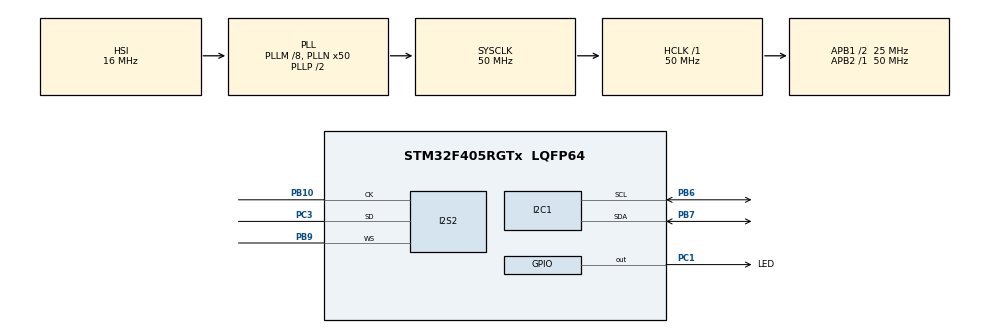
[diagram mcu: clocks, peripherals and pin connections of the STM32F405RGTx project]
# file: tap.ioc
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I2C1.I2C_Mode=I2C_Fast
I2S2.AudioFreq=I2S_AUDIOFREQ_11K
I2S2.ErrorAudioFreq=0.02 %
I2S2.FullDuplexMode=I2S_FULLDUPLEXMODE_DISABLE
I2S2.Instance=SPI$Index
I2S2.RealAudioFreq=11.003 KHz
I2S2.VirtualMode=I2S_MODE_MASTER
Mcu.Family=STM32F4
Mcu.Name=STM32F405RGTx
Mcu.Package=LQFP64
NVIC.PriorityGroup=NVIC_PRIORITYGROUP_4
PB10.Mode=Half_Duplex_Master
PB10.Signal=I2S2_CK
PB6.Mode=I2C
PB6.Signal=I2C1_SCL
PB7.Mode=I2C
PB7.Signal=I2C1_SDA
PB9.Mode=Half_Duplex_Master
PB9.Signal=I2S2_WS
PC1.GPIO_Label=LED
PC1.Signal=GPIO_Output
PC14-OSC32_IN.Mode=LSE-External-Oscillator
PC14-OSC32_IN.Signal=RCC_OSC32_IN
PC15-OSC32_OUT.Mode=LSE-External-Oscillator
PC15-OSC32_OUT.Signal=RCC_OSC32_OUT
PC3.Mode=Half_Duplex_Master
PC3.Signal=I2S2_SD
PH0-OSC_IN.Mode=HSE-External-Oscillator
PH0-OSC_IN.Signal=RCC_OSC_IN
PH1-OSC_OUT.Mode=HSE-External-Oscillator
PH1-OSC_OUT.Signal=RCC_OSC_OUT
ProjectManager.HeapSize=0x200
ProjectManager.StackSize=0x400
ProjectManager.TargetToolchain=STM32CubeIDE
RCC.48MHZClocksFreq_Value=25000000
RCC.AHBFreq_Value=50000000
RCC.APB1CLKDivider=RCC_HCLK_DIV2
RCC.APB1Freq_Value=25000000
RCC.APB1TimFreq_Value=50000000
RCC.APB2Freq_Value=50000000
RCC.APB2TimFreq_Value=50000000
RCC.CortexFreq_Value=50000000
RCC.HCLKFreq_Value=50000000
RCC.HSE_VALUE=12000000
RCC.HSI_VALUE=16000000
RCC.PLLI2SN=50
RCC.PLLM=8
RCC.PLLN=50
RCC.SYSCLKFreq_VALUE=50000000
RCC.SYSCLKSource=RCC_SYSCLKSOURCE_PLLCLK
RCC.VCOOutputFreq_Value=100000000
board=custom

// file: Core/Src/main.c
/* USER CODE BEGIN Header */
/**
  ******************************************************************************
  * @file           : main.c
  * @brief          : Main program body
  ******************************************************************************
  * @attention
  *
  * <h2><center>&copy; Copyright (c) 2020 STMicroelectronics.
  * All rights reserved.</center></h2>
  *
  * This software component is licensed by ST under BSD 3-Clause license,
  * the "License"; You may not use this file except in compliance with the
  * License. You may obtain a copy of the License at:
  *                        opensource.org/licenses/BSD-3-Clause
  *
  ******************************************************************************
  */
/* USER CODE END Header */
#include "main.h"

/* USER CODE BEGIN Includes */
extern void init(I2C_HandleTypeDef i2c1, I2S_HandleTypeDef i2s2);

/* USER CODE END Includes */

I2C_HandleTypeDef hi2c1;

I2S_HandleTypeDef hi2s2;

void SystemClock_Config(void);
static void MX_GPIO_Init(void);
static void MX_I2C1_Init(void);
static void MX_I2S2_Init(void);

int main(void)
{

  /* MCU Configuration--------------------------------------------------------*/

  /* Reset of all peripherals, Initializes the Flash interface and the Systick. */
  HAL_Init();

  /* Configure the system clock */
  SystemClock_Config();

  /* Initialize all configured peripherals */
  MX_GPIO_Init();
  MX_I2C1_Init();
  MX_I2S2_Init();

  /* Infinite loop */
  while (1)
  {

    /* USER CODE BEGIN 3 */
	    init(hi2c1, hi2s2);
		//HAL_GPIO_TogglePin(GPIOC, LED_Pin);
		//HAL_Delay(500);

  }
  /* USER CODE END 3 */
}

void SystemClock_Config(void)
{
  RCC_OscInitTypeDef RCC_OscInitStruct = {0};
  RCC_ClkInitTypeDef RCC_ClkInitStruct = {0};
  RCC_PeriphCLKInitTypeDef PeriphClkInitStruct = {0};

  /** Configure the main internal regulator output voltage
  */
  __HAL_RCC_PWR_CLK_ENABLE();
  __HAL_PWR_VOLTAGESCALING_CONFIG(PWR_REGULATOR_VOLTAGE_SCALE1);
  /** Initializes the RCC Oscillators according to the specified parameters
  * in the RCC_OscInitTypeDef structure.
  */
  RCC_OscInitStruct.OscillatorType = RCC_OSCILLATORTYPE_HSI;
  RCC_OscInitStruct.HSIState = RCC_HSI_ON;
  RCC_OscInitStruct.HSICalibrationValue = RCC_HSICALIBRATION_DEFAULT;
  RCC_OscInitStruct.PLL.PLLState = RCC_PLL_ON;
  RCC_OscInitStruct.PLL.PLLSource = RCC_PLLSOURCE_HSI;
  RCC_OscInitStruct.PLL.PLLM = 8;
  RCC_OscInitStruct.PLL.PLLN = 50;
  RCC_OscInitStruct.PLL.PLLP = RCC_PLLP_DIV2;
  RCC_OscInitStruct.PLL.PLLQ = 4;
  if (HAL_RCC_OscConfig(&RCC_OscInitStruct) != HAL_OK)
  {
    Error_Handler();
  }
  /** Initializes the CPU, AHB and APB buses clocks
  */
  RCC_ClkInitStruct.ClockType = RCC_CLOCKTYPE_HCLK|RCC_CLOCKTYPE_SYSCLK
                              |RCC_CLOCKTYPE_PCLK1|RCC_CLOCKTYPE_PCLK2;
  RCC_ClkInitStruct.SYSCLKSource = RCC_SYSCLKSOURCE_PLLCLK;
  RCC_ClkInitStruct.AHBCLKDivider = RCC_SYSCLK_DIV1;
  RCC_ClkInitStruct.APB1CLKDivider = RCC_HCLK_DIV2;
  RCC_ClkInitStruct.APB2CLKDivider = RCC_HCLK_DIV1;

  if (HAL_RCC_ClockConfig(&RCC_ClkInitStruct, FLASH_LATENCY_1) != HAL_OK)
  {
    Error_Handler();
  }
  PeriphClkInitStruct.PeriphClockSelection = RCC_PERIPHCLK_I2S;
  PeriphClkInitStruct.PLLI2S.PLLI2SN = 50;
  PeriphClkInitStruct.PLLI2S.PLLI2SR = 2;
  if (HAL_RCCEx_PeriphCLKConfig(&PeriphClkInitStruct) != HAL_OK)
  {
    Error_Handler();
  }
}

static void MX_I2C1_Init(void)
{

  hi2c1.Instance = I2C1;
  hi2c1.Init.ClockSpeed = 400000;
  hi2c1.Init.DutyCycle = I2C_DUTYCYCLE_2;
  hi2c1.Init.OwnAddress1 = 0;
  hi2c1.Init.AddressingMode = I2C_ADDRESSINGMODE_7BIT;
  hi2c1.Init.DualAddressMode = I2C_DUALADDRESS_DISABLE;
  hi2c1.Init.OwnAddress2 = 0;
  hi2c1.Init.GeneralCallMode = I2C_GENERALCALL_DISABLE;
  hi2c1.Init.NoStretchMode = I2C_NOSTRETCH_DISABLE;
  if (HAL_I2C_Init(&hi2c1) != HAL_OK)
  {
    Error_Handler();
  }

}

static void MX_I2S2_Init(void)
{

  hi2s2.Instance = SPI2;
  hi2s2.Init.Mode = I2S_MODE_MASTER_TX;
  hi2s2.Init.Standard = I2S_STANDARD_PHILIPS;
  hi2s2.Init.DataFormat = I2S_DATAFORMAT_16B;
  hi2s2.Init.MCLKOutput = I2S_MCLKOUTPUT_DISABLE;
  hi2s2.Init.AudioFreq = I2S_AUDIOFREQ_11K;
  hi2s2.Init.CPOL = I2S_CPOL_LOW;
  hi2s2.Init.ClockSource = I2S_CLOCK_PLL;
  hi2s2.Init.FullDuplexMode = I2S_FULLDUPLEXMODE_DISABLE;
  if (HAL_I2S_Init(&hi2s2) != HAL_OK)
  {
    Error_Handler();
  }

}

static void MX_GPIO_Init(void)
{
  GPIO_InitTypeDef GPIO_InitStruct = {0};

  /* GPIO Ports Clock Enable */
  __HAL_RCC_GPIOC_CLK_ENABLE();
  __HAL_RCC_GPIOH_CLK_ENABLE();
  __HAL_RCC_GPIOB_CLK_ENABLE();

  /*Configure GPIO pin Output Level */
  HAL_GPIO_WritePin(LED_GPIO_Port, LED_Pin, GPIO_PIN_RESET);

  /*Configure GPIO pin : LED_Pin */
  GPIO_InitStruct.Pin = LED_Pin;
  GPIO_InitStruct.Mode = GPIO_MODE_OUTPUT_PP;
  GPIO_InitStruct.Pull = GPIO_NOPULL;
  GPIO_InitStruct.Speed = GPIO_SPEED_FREQ_LOW;
  HAL_GPIO_Init(LED_GPIO_Port, &GPIO_InitStruct);

}

void Error_Handler(void)
{
}

/************************ (C) COPYRIGHT STMicroelectronics *****END OF FILE****/
